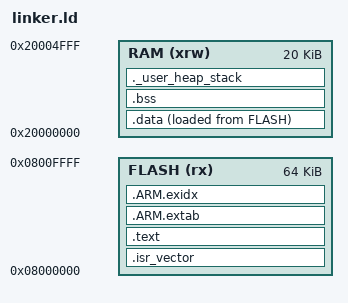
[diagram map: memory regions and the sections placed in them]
ENTRY(Reset_Handler)

MEMORY
{
    FLASH (rx)  : ORIGIN = 0x08000000, LENGTH = 64K
    RAM   (xrw) : ORIGIN = 0x20000000, LENGTH = 20K
}

_estack = ORIGIN(RAM) + LENGTH(RAM);
_Min_Heap_Size = 0x200;
_Min_Stack_Size = 0x400;

SECTIONS
{
    .isr_vector :
    {
        . = ALIGN(4);
        KEEP(*(.isr_vector))
        . = ALIGN(4);
    } > FLASH

    .text :
    {
        . = ALIGN(4);
        *(.text)
        *(.text*)
        *(.rodata)
        *(.rodata*)
        . = ALIGN(4);
    } > FLASH

    .ARM.extab :
    {
        *(.ARM.extab* .gnu.linkonce.armextab.*)
    } > FLASH

    .ARM.exidx :
    {
        __exidx_start = .;
        *(.ARM.exidx* .gnu.linkonce.armexidx.*)
        __exidx_end = .;
    } > FLASH

    .data :
    {
        . = ALIGN(4);
        _sdata = .;
        *(.data)
        *(.data*)
        . = ALIGN(4);
        _edata = .;
    } > RAM AT > FLASH

    _sidata = LOADADDR(.data);

    .bss (NOLOAD) :
    {
        . = ALIGN(4);
        _sbss = .;
        *(.bss)
        *(.bss*)
        *(COMMON)
        . = ALIGN(4);
        _ebss = .;
        _end = .;
        end = .;
    } > RAM

    ._user_heap_stack (NOLOAD) :
    {
        . = ALIGN(8);
        . = . + _Min_Heap_Size;
        . = . + _Min_Stack_Size;
        . = ALIGN(8);
    } > RAM
}
